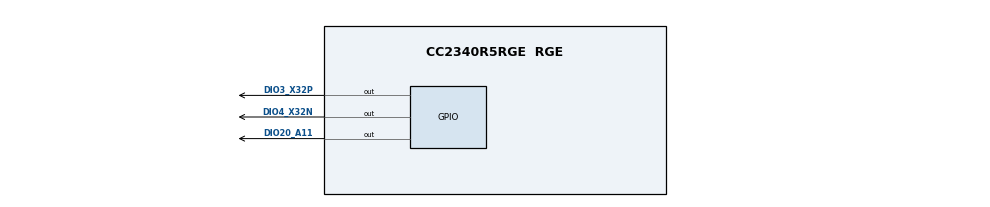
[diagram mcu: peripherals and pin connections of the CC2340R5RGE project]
/**
 * @cliArgs --device "CC2340R5RGE" --part "Default" --package "RGE" --rtos "nortos" --product "simplelink_lowpower_f3_sdk@8.40.02.01"
 * @versions {"tool":"1.22.0+3893"}
 */

/**
 * Import the modules used in this configuration.
 */
const mcuboot = scripting.addModule("/ti/common/mcuboot");
const CCFG    = scripting.addModule("/ti/devices/CCFG");
const Board   = scripting.addModule("/ti/drivers/Board");
const GPIO    = scripting.addModule("/ti/drivers/GPIO");
const GPIO1   = GPIO.addInstance();
const GPIO2   = GPIO.addInstance();
const GPIO3   = GPIO.addInstance();

/**
 * Write custom configuration values to the imported modules.
 */
mcuboot.mode           = "overwrite";
mcuboot.bootloaderSize = 0x00004000;
mcuboot.primaryBase1   = 0x00004000;
mcuboot.primarySize1   = 0x0003D800;
mcuboot.secondarySize1 = 0x0003D800;
mcuboot.secondaryBase1 = 0x00041800;

CCFG.ccfgTemplate.$name = "ti_devices_CCFG_CCFGCC26XXTemplate0";

GPIO1.mode            = "Output";
GPIO1.$name           = "CONFIG_GPIO_LED_0";
GPIO1.gpioPin.$assign = "DIO3_X32P";

GPIO2.mode            = "Output";
GPIO2.$name           = "CONFIG_GPIO_LED_1";
GPIO2.gpioPin.$assign = "DIO4_X32N";

GPIO3.$name           = "CONFIG_GPIO_BUTTON_0";
GPIO3.gpioPin.$assign = "DIO20_A11";
